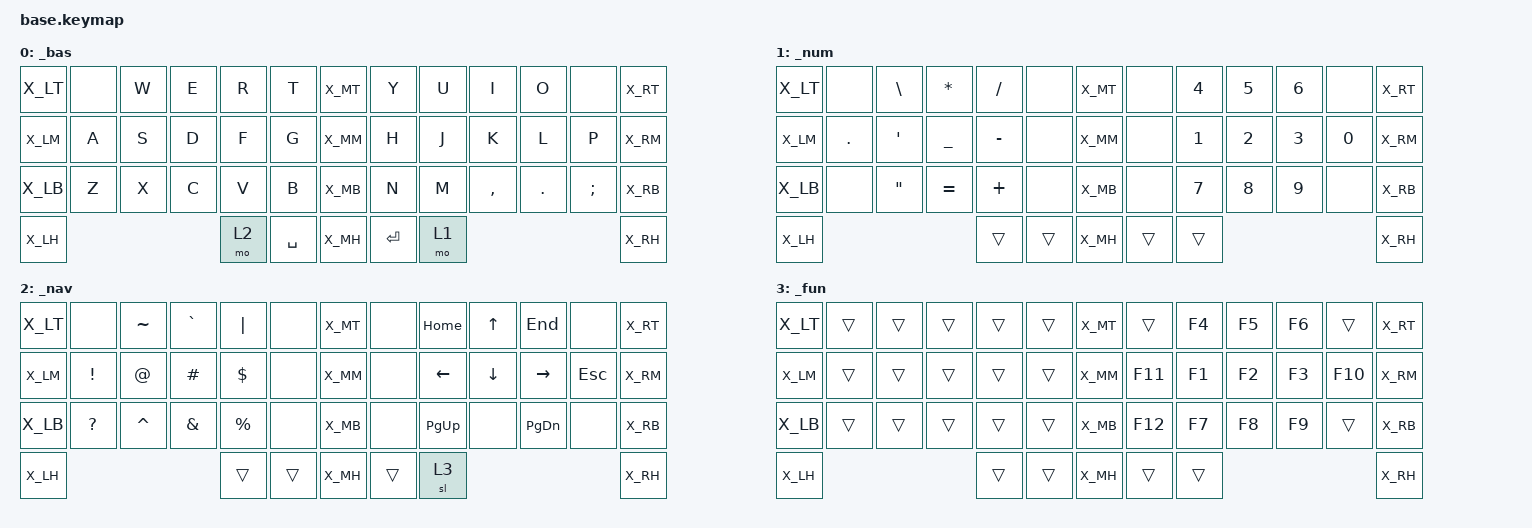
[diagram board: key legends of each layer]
#include <behaviors.dtsi>
#include <dt-bindings/zmk/keys.h>
#include "zmk-helpers/helper.h"

#define _bas 0
#define _num 1
#define _nav 2
#define _fun 3
#define _gam 4

#include "combos.dtsi"  // requires layer aliases
#include "mouse.dtsi"
#include "extra_keys.h"

#define XXX &none
#define ___ &trans

#define KEYS_L LT0 LT1 LT2 LT3 LT4 LM0 LM1 LM2 LM3 LM4 LB0 LB1 LB2 LB3 LB4  // left hand
#define KEYS_R RT0 RT1 RT2 RT3 RT4 RM0 RM1 RM2 RM3 RM4 RB0 RB1 RB2 RB3 RB4  // right hand
#define THUMBS LH2 LH1 LH0 RH0 RH1 RH2                                      // thumbs

/* Keymap */

ZMK_LAYER(_bas,
//╭──────╮ ╭─────────────┬─────────────┬─────────────┬─────────────┬─────────────╮ ╭──────╮ ╭─────────────┬─────────────┬─────────────┬─────────────┬─────────────╮ ╭──────╮
    X_LT         &none        &kp W          &kp E          &kp R         &kp T      X_MT     &kp Y          &kp U          &kp I          &kp O        &none         X_RT
    X_LM         &kp A        &kp S          &kp D          &kp F         &kp G      X_MM     &kp H          &kp J          &kp K          &kp L        &kp P         X_RM
    X_LB         &kp Z        &kp X          &kp C          &kp V         &kp B      X_MB     &kp N          &kp M          &kp COMMA      &kp DOT      &kp SEMI      X_RB
//├──────┤ ╰─────────────┼─────────────┴─────────────┼─────────────┼─────────────┤ ├──────┤ ├─────────────┼─────────────┼─────────────┴───────────────────────────╯ ├──────┤
    X_LH                                                  &mo 2       &kp SPACE      X_MH     &kp ENTER      &mo 1                                                    X_RH
//╰──────╯                                           ╰─────────────┴─────────────╯ ╰──────╯ ╰─────────────┴─────────────╯                                           ╰──────╯
)

ZMK_LAYER(_num,
//╭──────╮ ╭─────────────┬─────────────┬─────────────┬─────────────┬─────────────╮ ╭──────╮ ╭─────────────┬─────────────┬─────────────┬─────────────┬─────────────╮ ╭──────╮
    X_LT        &none         &kp BSLH      &kp STAR     &kp FSLH       &none        X_MT       &none         &kp N4          &kp N5      &kp N6      &none           X_RT
    X_LM        &kp DOT       &kp SQT       &kp UNDER    &kp MINUS      &none        X_MM       &none         &kp N1          &kp N2      &kp N3      &kp N0          X_RM
    X_LB        &none         &kp DQT       &kp EQUAL    &kp PLUS       &none        X_MB       &none         &kp N7          &kp N8      &kp N9      &none           X_RB
//├──────┤ ╰─────────────┼─────────────┴─────────────┼─────────────┼─────────────┤ ├──────┤ ├─────────────┼─────────────┼─────────────┴───────────────────────────╯ ├──────┤
    X_LH                                                   ___           ___         X_MH        ___           ___                                                    X_RH
//╰──────╯                                           ╰─────────────┴─────────────╯ ╰──────╯ ╰─────────────┴─────────────╯                                           ╰──────╯
)

ZMK_LAYER(_nav,
//╭──────╮ ╭─────────────┬─────────────┬─────────────┬─────────────┬─────────────╮ ╭──────╮ ╭─────────────┬─────────────┬─────────────┬─────────────┬─────────────╮ ╭──────╮
    X_LT     &none          &kp TILDE      &kp GRAVE  &kp PIPE       &none           X_MT     &none          &kp HOME       &kp UP        &kp END        &none        X_RT
    X_LM     &kp EXCL       &kp AT         &kp POUND  &kp DLLR       &none           X_MM     &none          &kp LEFT       &kp DOWN      &kp RIGHT      &kp ESC      X_RM
    X_LB     &kp QMARK      &kp CARET      &kp AMPS   &kp PRCNT      &none           X_MB     &none          &kp PG_UP       &none        &kp PG_DN      &none        X_RB
//├──────┤ ╰─────────────┼─────────────┴─────────────┼─────────────┼─────────────┤ ├──────┤ ├─────────────┼─────────────┼─────────────┴───────────────────────────╯ ├──────┤
    X_LH                                               ___           ___             X_MH         ___           &sl 3                                                 X_RH
//╰──────╯                                           ╰─────────────┴─────────────╯ ╰──────╯ ╰─────────────┴─────────────╯                                           ╰──────╯
)

ZMK_LAYER(_fun,
//╭──────╮ ╭─────────────┬─────────────┬─────────────┬─────────────┬─────────────╮ ╭──────╮ ╭─────────────┬─────────────┬─────────────┬─────────────┬─────────────╮ ╭──────╮
    X_LT      ___           ___           ___           ___           ___            X_MT     ___           &kp F4          &kp F5       &kp F6        ___             X_RT
    X_LM     ___           ___           ___           ___           ___             X_MM     &kp F11       &kp F1          &kp F2       &kp F3          &kp F10      X_RM
    X_LB      ___           ___           ___           ___           ___            X_MB     &kp F12          &kp F7      &kp F8        &kp F9          ___        X_RB
//├──────┤ ╰─────────────┼─────────────┴─────────────┼─────────────┼─────────────┤ ├──────┤ ├─────────────┼─────────────┼─────────────┴───────────────────────────╯ ├──────┤
    X_LH                                               ___           ___             X_MH     ___           ___                                                       X_RH
//╰──────╯                                           ╰─────────────┴─────────────╯ ╰──────╯ ╰─────────────┴─────────────╯                                           ╰──────╯
)

